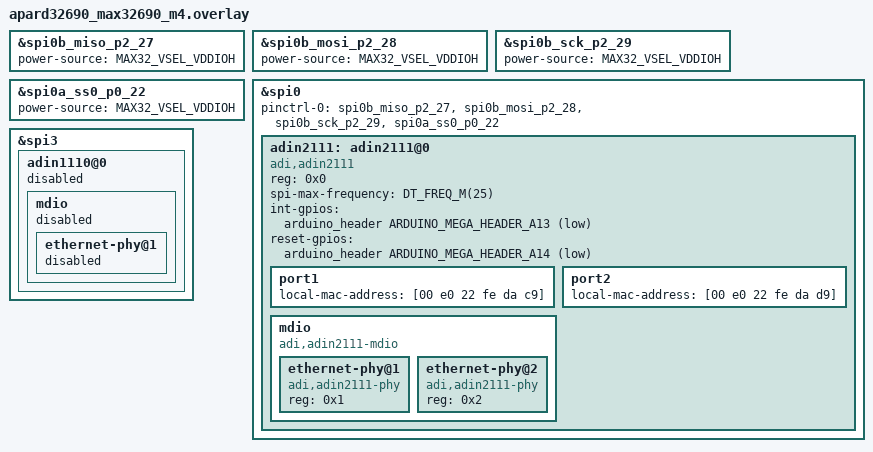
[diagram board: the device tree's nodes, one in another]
/*
 * Copyright (c) 2026 Analog Devices, Inc.
 *
 * SPDX-License-Identifier: Apache-2.0
 */

#include <freq.h>
#include <zephyr/dt-bindings/gpio/gpio.h>
#include <zephyr/dt-bindings/gpio/adi-max32-gpio.h>
#include <zephyr/dt-bindings/gpio/arduino-mega-header.h>

&spi0b_miso_p2_27 {
	power-source = <MAX32_VSEL_VDDIOH>;
};

&spi0b_mosi_p2_28 {
	power-source = <MAX32_VSEL_VDDIOH>;
};

&spi0b_sck_p2_29 {
	power-source = <MAX32_VSEL_VDDIOH>;
};

&spi0a_ss0_p0_22 {
	power-source = <MAX32_VSEL_VDDIOH>;
};

&spi0 {
	pinctrl-0 = <&spi0b_miso_p2_27 &spi0b_mosi_p2_28 &spi0b_sck_p2_29
		     &spi0a_ss0_p0_22>;
	pinctrl-names = "default";
	status = "okay";

	adin2111: adin2111@0 {
		compatible = "adi,adin2111";
		reg = <0x0>;
		spi-max-frequency = <DT_FREQ_M(25)>;
		int-gpios = <&arduino_header ARDUINO_MEGA_HEADER_A13
			     (GPIO_ACTIVE_LOW | MAX32_GPIO_VSEL_VDDIOH)>;
		reset-gpios = <&arduino_header ARDUINO_MEGA_HEADER_A14
			       (GPIO_ACTIVE_LOW | MAX32_GPIO_VSEL_VDDIOH)>;
		status = "okay";

		port1 {
			local-mac-address = [00 e0 22 fe da c9];
		};

		port2 {
			local-mac-address = [00 e0 22 fe da d9];
		};

		mdio {
			compatible = "adi,adin2111-mdio";
			#address-cells = <1>;
			#size-cells = <0>;

			ethernet-phy@1 {
				reg = <0x1>;
				compatible = "adi,adin2111-phy";
			};

			ethernet-phy@2 {
				reg = <0x2>;
				compatible = "adi,adin2111-phy";
			};
		};
	};
};

&spi3 {
	adin1110@0 {
		status = "disabled";

		mdio {
			status = "disabled";

			ethernet-phy@1 {
				status = "disabled";
			};
		};
	};
};
